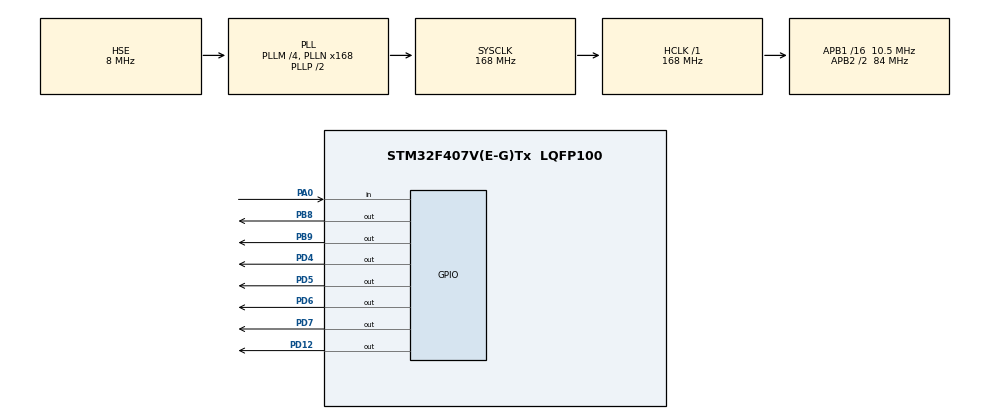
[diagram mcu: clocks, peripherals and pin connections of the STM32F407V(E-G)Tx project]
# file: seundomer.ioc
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Mcu.Family=STM32F4
Mcu.Name=STM32F407V(E-G)Tx
Mcu.Package=LQFP100
NVIC.PriorityGroup=NVIC_PRIORITYGROUP_4
NVIC.TIM6_DAC_IRQn=true\:0\:0\:false\:false\:true
PA0-WKUP.Signal=GPIO_Input
PB8.Signal=GPIO_Output
PB9.Signal=GPIO_Output
PD12.Signal=GPIO_Output
PD4.Signal=GPIO_Output
PD5.Signal=GPIO_Output
PD6.Signal=GPIO_Output
PD7.Signal=GPIO_Output
PH0-OSC_IN.Mode=HSE-External-Oscillator
PH0-OSC_IN.Signal=RCC_OSC_IN
PH1-OSC_OUT.Mode=HSE-External-Oscillator
PH1-OSC_OUT.Signal=RCC_OSC_OUT
ProjectManager.HeapSize=0x200
ProjectManager.StackSize=0x400
ProjectManager.TargetToolchain=MDK-ARM V5
RCC.48MHZClocksFreq_Value=84000000
RCC.AHBFreq_Value=168000000
RCC.APB1CLKDivider=RCC_HCLK_DIV16
RCC.APB1Freq_Value=10500000
RCC.APB1TimFreq_Value=21000000
RCC.APB2CLKDivider=RCC_HCLK_DIV2
RCC.APB2Freq_Value=84000000
RCC.APB2TimFreq_Value=168000000
RCC.CortexFreq_Value=168000000
RCC.HCLKFreq_Value=168000000
RCC.HSE_VALUE=8000000
RCC.HSI_VALUE=16000000
RCC.LSE_VALUE=32768
RCC.PLLM=4
RCC.PLLN=168
RCC.PLLSourceVirtual=RCC_PLLSOURCE_HSE
RCC.SYSCLKFreq_VALUE=168000000
RCC.SYSCLKSource=RCC_SYSCLKSOURCE_PLLCLK
RCC.VCOOutputFreq_Value=336000000
TIM6.Period=999
TIM6.Prescaler=20999
TIM6.TIM_MasterOutputTrigger=TIM_TRGO_UPDATE
VP_TIM6_VS_ClockSourceINT.Mode=Enable_Timer
board=seundomer

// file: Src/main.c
/**
  ******************************************************************************
  * File Name          : main.c
  * Description        : Main program body
  ******************************************************************************
  *
  * COPYRIGHT(c) 2017 STMicroelectronics
  *
  * Redistribution and use in source and binary forms, with or without modification,
  * are permitted provided that the following conditions are met:
  *   1. Redistributions of source code must retain the above copyright notice,
  *      this list of conditions and the following disclaimer.
  *   2. Redistributions in binary form must reproduce the above copyright notice,
  *      this list of conditions and the following disclaimer in the documentation
  *      and/or other materials provided with the distribution.
  *   3. Neither the name of STMicroelectronics nor the names of its contributors
  *      may be used to endorse or promote products derived from this software
  *      without specific prior written permission.
  *
  * THIS SOFTWARE IS PROVIDED BY THE COPYRIGHT HOLDERS AND CONTRIBUTORS "AS IS"
  * AND ANY EXPRESS OR IMPLIED WARRANTIES, INCLUDING, BUT NOT LIMITED TO, THE
  * IMPLIED WARRANTIES OF MERCHANTABILITY AND FITNESS FOR A PARTICULAR PURPOSE ARE
  * DISCLAIMED. IN NO EVENT SHALL THE COPYRIGHT HOLDER OR CONTRIBUTORS BE LIABLE
  * FOR ANY DIRECT, INDIRECT, INCIDENTAL, SPECIAL, EXEMPLARY, OR CONSEQUENTIAL
  * DAMAGES (INCLUDING, BUT NOT LIMITED TO, PROCUREMENT OF SUBSTITUTE GOODS OR
  * SERVICES; LOSS OF USE, DATA, OR PROFITS; OR BUSINESS INTERRUPTION) HOWEVER
  * CAUSED AND ON ANY THEORY OF LIABILITY, WHETHER IN CONTRACT, STRICT LIABILITY,
  * OR TORT (INCLUDING NEGLIGENCE OR OTHERWISE) ARISING IN ANY WAY OUT OF THE USE
  * OF THIS SOFTWARE, EVEN IF ADVISED OF THE POSSIBILITY OF SUCH DAMAGE.
  *
  ******************************************************************************
  */
#include "main.h"
#include "stm32f4xx_hal.h"

/* USER CODE BEGIN Includes */

uint8_t second=0;
uint8_t min=0;
uint8_t house=0;

/* USER CODE END Includes */

TIM_HandleTypeDef htim6;
uint8_t count_button=0;
/* USER CODE BEGIN PV */
/* Private variables ---------------------------------------------------------*/

/* USER CODE END PV */

void SystemClock_Config(void);
void Error_Handler(void);
static void MX_GPIO_Init(void);
static void MX_TIM6_Init(void);

/* USER CODE BEGIN PFP */
/* Private function prototypes -----------------------------------------------*/

/* USER CODE END PFP */

int main(void)
{

  /* MCU Configuration----------------------------------------------------------*/

  /* Reset of all peripherals, Initializes the Flash interface and the Systick. */
  HAL_Init();

  /* Configure the system clock */
  SystemClock_Config();

  /* Initialize all configured peripherals */
  MX_GPIO_Init();
  MX_TIM6_Init();
	LCD_ini();
	LCD_GOTOXY(5,0);
	LCD_printstring("Hello user!!!");
	HAL_TIM_Base_Start(&htim6);

  while (1)
  {
		if(HAL_GPIO_ReadPin(GPIOA,GPIO_PIN_0)==GPIO_PIN_SET)
		{
			 count_button++;
			if(count_button>3)
			{
				count_button=0;
			}

		}
		if(count_button==1)
		{
			HAL_TIM_Base_Start(&htim6);
      HAL_TIM_Base_Start_IT(&htim6);

			LCD_GOTOXY(1,1);
			LCD_printstring("Timer!!!");
			LCD_GOTOXY(1,2);
			LCD_printchar((house/10)+0x30);
			LCD_printchar((house%10)+0x30);
			LCD_printchar(':');
			LCD_printchar((min/10)+0x30);
			LCD_printchar((min%10)+0x30);
			LCD_printchar(':');
			LCD_printchar((second/10)+0x30);
			LCD_printchar((second%10)+0x30);

		}
			else if(count_button==2)
			{
				HAL_TIM_Base_Stop(&htim6);
      HAL_TIM_Base_Stop_IT(&htim6);
			LCD_GOTOXY(1,2);
			LCD_printchar((house/10)+0x30);
			LCD_printchar((house%10)+0x30);
			LCD_printchar(':');
			LCD_printchar((min/10)+0x30);
			LCD_printchar((min%10)+0x30);
			LCD_printchar(':');
			LCD_printchar((second/10)+0x30);
			LCD_printchar((second%10)+0x30);
			}

  }

}

/** System Clock Configuration
*/
void SystemClock_Config(void)
{

  RCC_OscInitTypeDef RCC_OscInitStruct;
  RCC_ClkInitTypeDef RCC_ClkInitStruct;

    /**Configure the main internal regulator output voltage
    */
  __HAL_RCC_PWR_CLK_ENABLE();

  __HAL_PWR_VOLTAGESCALING_CONFIG(PWR_REGULATOR_VOLTAGE_SCALE1);

    /**Initializes the CPU, AHB and APB busses clocks
    */
  RCC_OscInitStruct.OscillatorType = RCC_OSCILLATORTYPE_HSE;
  RCC_OscInitStruct.HSEState = RCC_HSE_ON;
  RCC_OscInitStruct.PLL.PLLState = RCC_PLL_ON;
  RCC_OscInitStruct.PLL.PLLSource = RCC_PLLSOURCE_HSE;
  RCC_OscInitStruct.PLL.PLLM = 4;
  RCC_OscInitStruct.PLL.PLLN = 168;
  RCC_OscInitStruct.PLL.PLLP = RCC_PLLP_DIV2;
  RCC_OscInitStruct.PLL.PLLQ = 4;
  if (HAL_RCC_OscConfig(&RCC_OscInitStruct) != HAL_OK)
  {
    Error_Handler();
  }

    /**Initializes the CPU, AHB and APB busses clocks
    */
  RCC_ClkInitStruct.ClockType = RCC_CLOCKTYPE_HCLK|RCC_CLOCKTYPE_SYSCLK
                              |RCC_CLOCKTYPE_PCLK1|RCC_CLOCKTYPE_PCLK2;
  RCC_ClkInitStruct.SYSCLKSource = RCC_SYSCLKSOURCE_PLLCLK;
  RCC_ClkInitStruct.AHBCLKDivider = RCC_SYSCLK_DIV1;
  RCC_ClkInitStruct.APB1CLKDivider = RCC_HCLK_DIV16;
  RCC_ClkInitStruct.APB2CLKDivider = RCC_HCLK_DIV2;

  if (HAL_RCC_ClockConfig(&RCC_ClkInitStruct, FLASH_LATENCY_5) != HAL_OK)
  {
    Error_Handler();
  }

    /**Configure the Systick interrupt time
    */
  HAL_SYSTICK_Config(HAL_RCC_GetHCLKFreq()/1000);

    /**Configure the Systick
    */
  HAL_SYSTICK_CLKSourceConfig(SYSTICK_CLKSOURCE_HCLK);

  /* SysTick_IRQn interrupt configuration */
  HAL_NVIC_SetPriority(SysTick_IRQn, 0, 0);
}

/* TIM6 init function */
static void MX_TIM6_Init(void)
{

  TIM_MasterConfigTypeDef sMasterConfig;

  htim6.Instance = TIM6;
  htim6.Init.Prescaler = 20999;
  htim6.Init.CounterMode = TIM_COUNTERMODE_UP;
  htim6.Init.Period = 999;
  if (HAL_TIM_Base_Init(&htim6) != HAL_OK)
  {
    Error_Handler();
  }

  sMasterConfig.MasterOutputTrigger = TIM_TRGO_UPDATE;
  sMasterConfig.MasterSlaveMode = TIM_MASTERSLAVEMODE_DISABLE;
  if (HAL_TIMEx_MasterConfigSynchronization(&htim6, &sMasterConfig) != HAL_OK)
  {
    Error_Handler();
  }

}

/** Configure pins as
        * Analog
        * Input
        * Output
        * EVENT_OUT
        * EXTI
*/
static void MX_GPIO_Init(void)
{

  GPIO_InitTypeDef GPIO_InitStruct;

  /* GPIO Ports Clock Enable */
  __HAL_RCC_GPIOH_CLK_ENABLE();
  __HAL_RCC_GPIOA_CLK_ENABLE();
  __HAL_RCC_GPIOD_CLK_ENABLE();
  __HAL_RCC_GPIOB_CLK_ENABLE();

  /*Configure GPIO pin Output Level */
  HAL_GPIO_WritePin(GPIOD, GPIO_PIN_12|GPIO_PIN_4|GPIO_PIN_5|GPIO_PIN_6
                          |GPIO_PIN_7, GPIO_PIN_RESET);

  /*Configure GPIO pin Output Level */
  HAL_GPIO_WritePin(GPIOB, GPIO_PIN_8|GPIO_PIN_9, GPIO_PIN_RESET);

  /*Configure GPIO pin : PA0 */
  GPIO_InitStruct.Pin = GPIO_PIN_0;
  GPIO_InitStruct.Mode = GPIO_MODE_INPUT;
  GPIO_InitStruct.Pull = GPIO_NOPULL;
  HAL_GPIO_Init(GPIOA, &GPIO_InitStruct);

  /*Configure GPIO pins : PD12 PD4 PD5 PD6
                           PD7 */
  GPIO_InitStruct.Pin = GPIO_PIN_12|GPIO_PIN_4|GPIO_PIN_5|GPIO_PIN_6
                          |GPIO_PIN_7;
  GPIO_InitStruct.Mode = GPIO_MODE_OUTPUT_PP;
  GPIO_InitStruct.Pull = GPIO_NOPULL;
  GPIO_InitStruct.Speed = GPIO_SPEED_FREQ_LOW;
  HAL_GPIO_Init(GPIOD, &GPIO_InitStruct);

  /*Configure GPIO pins : PB8 PB9 */
  GPIO_InitStruct.Pin = GPIO_PIN_8|GPIO_PIN_9;
  GPIO_InitStruct.Mode = GPIO_MODE_OUTPUT_PP;
  GPIO_InitStruct.Pull = GPIO_NOPULL;
  GPIO_InitStruct.Speed = GPIO_SPEED_FREQ_LOW;
  HAL_GPIO_Init(GPIOB, &GPIO_InitStruct);

}

void Error_Handler(void)
{
  while(1)
  {
  }
}

/************************ (C) COPYRIGHT STMicroelectronics *****END OF FILE****/
